# STM32F103 register map
File version: 1.1
CPU: CM3 r1p1, little endian, no MPU, no FPU, 4 interrupt priority bits
Registers are 32-bit, read-write, reset 0x0 unless marked. A register's access mark holds for its fields unless they carry their own. Offsets are from the block's base; [hi:lo] are bit positions; lines under a group give offsets from that group; {n}, {i} and the like mark numbered series; <NAME> marks a mode.

## DBGMCU — Debug support
Base 0xE0042000
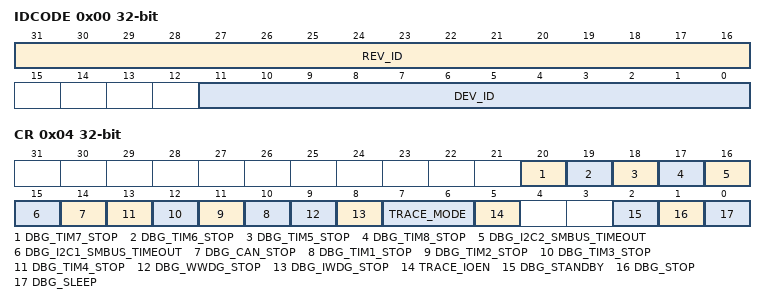
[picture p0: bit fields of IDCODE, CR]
0x00 IDCODE ro — DBGMCU_IDCODE
  [31:16] REV_ID, [11:0] DEV_ID
0x04 CR — DBGMCU_CR
  [20] DBG_TIM7_STOP, [19] DBG_TIM6_STOP, [18] DBG_TIM5_STOP, [17] DBG_TIM8_STOP, [16] DBG_I2C2_SMBUS_TIMEOUT, [15] DBG_I2C1_SMBUS_TIMEOUT, [14] DBG_CAN_STOP, [n+9] DBG_TIM{n}_STOP (n=1..4), [9] DBG_WWDG_STOP, [8] DBG_IWDG_STOP, [7:6] TRACE_MODE, [5] TRACE_IOEN, [2] DBG_STANDBY, [1] DBG_STOP, [0] DBG_SLEEP

## CRC — CRC calculation unit
Base 0x40023000
0x00 DR reset 0xFFFFFFFF — Data register
  [31:0] DR — Data Register
0x04 IDR — Independent Data register
  [7:0] IDR
0x08 CR wo — Control register
  [0] RESET — Reset bit
    1=Resets the CRC calculation unit and sets the data register to 0xFFFF FFFF

## FLASH
Base 0x40022000
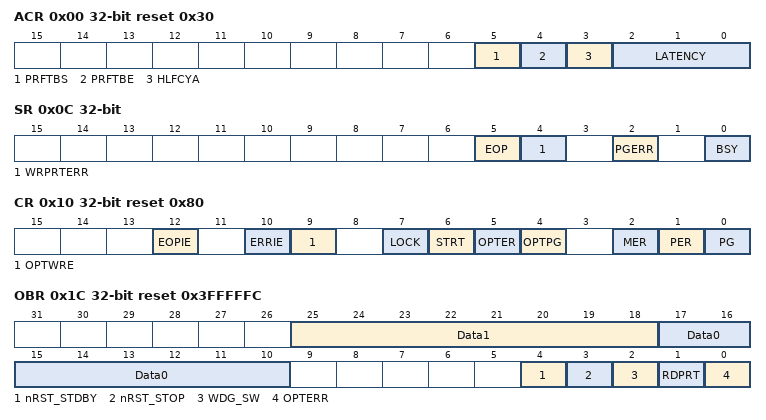
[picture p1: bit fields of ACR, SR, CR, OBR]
0x00 ACR access per field reset 0x30 — Flash access control register
  [5] PRFTBS ro — Prefetch buffer status
  [4] PRFTBE rw — Prefetch buffer enable
  [3] HLFCYA rw — Flash half cycle access enable
  [2:0] LATENCY rw
    0=WS0 (Zero wait state, if 0 < SYSCLK≤ 24 MHz); 1=WS1 (One wait state, if 24 MHz < SYSCLK ≤ 48 MHz); 2=WS2 (Two wait states, if 48 MHz < SYSCLK ≤ 72 MHz)
0x04 KEYR wo — Flash key register
  [31:0] KEY — FPEC key
0x08 OPTKEYR wo — Flash option key register
  [31:0] OPTKEY — Option byte key
0x0C SR access per field — Status register
  [5] EOP rw — End of operation
  [4] WRPRTERR rw — Write protection error
  [2] PGERR rw — Programming error
  [0] BSY ro — Busy
0x10 CR reset 0x80 — Control register
  [12] EOPIE — End of operation interrupt enable
  [10] ERRIE — Error interrupt enable
  [9] OPTWRE — Option bytes write enable
  [7] LOCK
  [6] STRT — Start
  [5] OPTER — Option byte erase
  [4] OPTPG — Option byte programming
  [2] MER — Mass Erase
  [1] PER — Page Erase
  [0] PG — Programming
0x14 AR wo — Flash address register
  [31:0] FAR — Flash Address
0x1C OBR ro reset 0x3FFFFFC — Option byte register
  [25:18] Data1
  [17:10] Data0
  [4] nRST_STDBY
  [3] nRST_STOP
  [2] WDG_SW
  [1] RDPRT — Read protection
  [0] OPTERR — Option byte error
0x20 WRPR ro reset 0xFFFFFFFF — Write protection register
  [31:0] WRP — Write protect

## OTG_FS_HOST — USB on the go full speed
Base 0x50000400
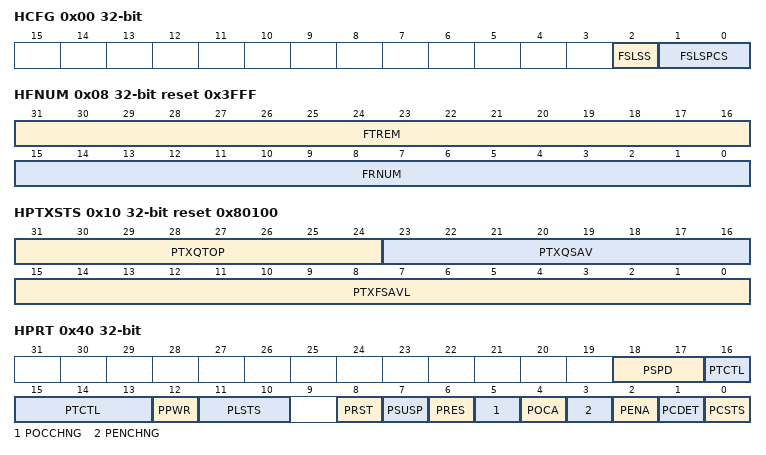
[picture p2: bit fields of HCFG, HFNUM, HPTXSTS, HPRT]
0x00 HCFG — OTG_FS host configuration register (OTG_FS_HCFG)
  [2] FSLSS — FS- and LS-only support
  [1:0] FSLSPCS — FS/LS PHY clock select
0x04 HFIR reset 0xEA60 — OTG_FS Host frame interval register
  [15:0] FRIVL — Frame interval
0x08 HFNUM ro reset 0x3FFF — OTG_FS host frame number/frame time remaining register (OTG_FS_HFNUM)
  [31:16] FTREM — Frame time remaining
  [15:0] FRNUM — Frame number
0x10 HPTXSTS access per field reset 0x80100 — OTG_FS_Host periodic transmit FIFO/queue status register (OTG_FS_HPTXSTS)
  [31:24] PTXQTOP ro — Top of the periodic transmit request queue
  [23:16] PTXQSAV ro — Periodic transmit request queue space available
  [15:0] PTXFSAVL rw — Periodic transmit data FIFO space available
0x14 HAINT ro — OTG_FS Host all channels interrupt register
  [15:0] HAINT — Channel interrupts
0x18 HAINTMSK — OTG_FS host all channels interrupt mask register
  [15:0] HAINTM — Channel interrupt mask
0x40 HPRT access per field — OTG_FS host port control and status register (OTG_FS_HPRT)
  [18:17] PSPD ro — Port speed
  [16:13] PTCTL rw — Port test control
  [12] PPWR rw — Port power
  [11:10] PLSTS ro — Port line status
  [8] PRST rw — Port reset
  [7] PSUSP rw — Port suspend
  [6] PRES rw — Port resume
  [5] POCCHNG rw — Port overcurrent change
  [4] POCA ro — Port overcurrent active
  [3] PENCHNG rw — Port enable/disable change
  [2] PENA rw — Port enable
  [1] PCDET rw — Port connect detected
  [0] PCSTS ro — Port connect status
{0x100+0x20*i} HC{i} (i=0..7) group — Host channel
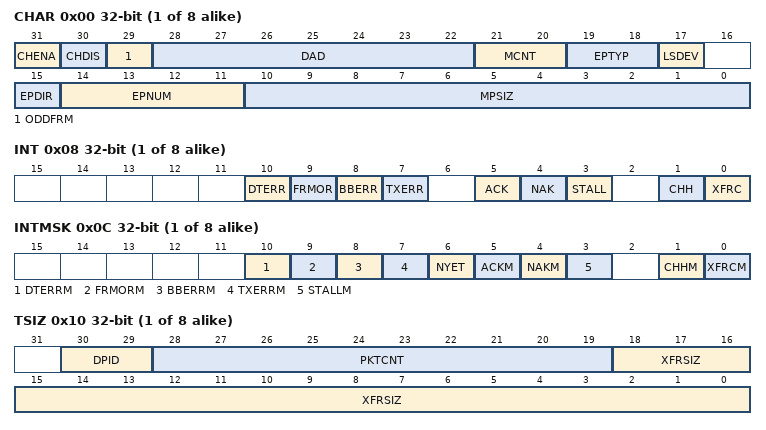
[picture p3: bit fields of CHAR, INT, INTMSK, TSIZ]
  0x00 CHAR — OTG_FS host channel-0 characteristics register (OTG_FS_HCCHAR0)
    [31] CHENA — Channel enable
    [30] CHDIS — Channel disable
    [29] ODDFRM — Odd frame
    [28:22] DAD — Device address
    [21:20] MCNT — Multicount
    [19:18] EPTYP — Endpoint type
    [17] LSDEV — Low-speed device
    [15] EPDIR — Endpoint direction
    [14:11] EPNUM — Endpoint number
    [10:0] MPSIZ — Maximum packet size
  0x08 INT — OTG_FS host channel-0 interrupt register (OTG_FS_HCINT0)
    [10] DTERR — Data toggle error
    [9] FRMOR — Frame overrun
    [8] BBERR — Babble error
    [7] TXERR — Transaction error
    [5] ACK — ACK response received/transmitted interrupt
    [4] NAK — NAK response received interrupt
    [3] STALL — STALL response received interrupt
    [1] CHH — Channel halted
    [0] XFRC — Transfer completed
  0x0C INTMSK — OTG_FS host channel-0 mask register (OTG_FS_HCINTMSK0)
    [10] DTERRM — Data toggle error mask
    [9] FRMORM — Frame overrun mask
    [8] BBERRM — Babble error mask
    [7] TXERRM — Transaction error mask
    [6] NYET — response received interrupt mask
    [5] ACKM — ACK response received/transmitted interrupt mask
    [4] NAKM — NAK response received interrupt mask
    [3] STALLM — STALL response received interrupt mask
    [1] CHHM — Channel halted mask
    [0] XFRCM — Transfer completed mask
  0x10 TSIZ — OTG_FS host channel-0 transfer size register
    [30:29] DPID — Data PID
    [28:19] PKTCNT — Packet count
    [18:0] XFRSIZ — Transfer size
